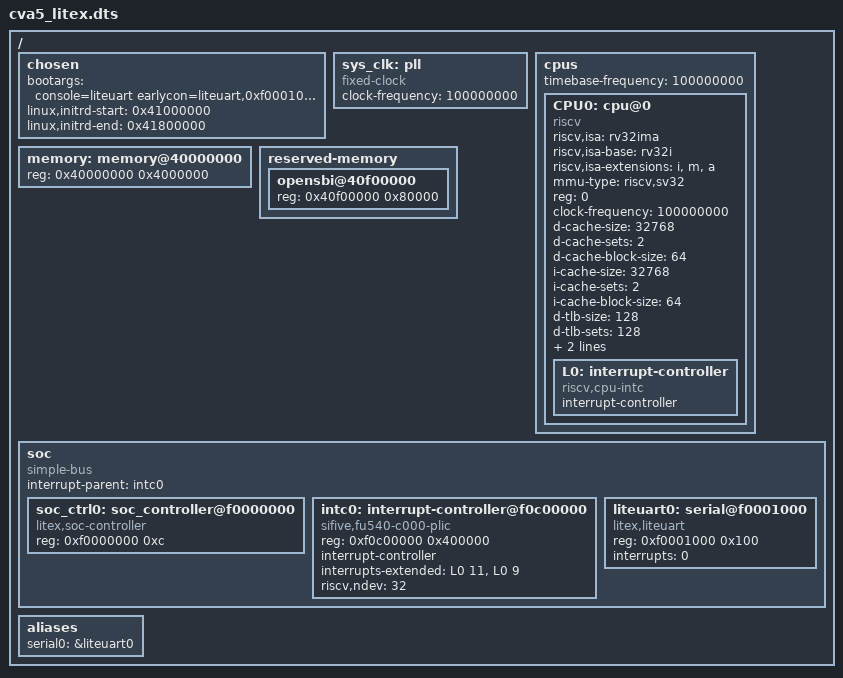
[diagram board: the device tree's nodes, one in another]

/dts-v1/;

/ {
        #address-cells = <1>;
        #size-cells    = <1>;


        chosen {
            bootargs = "console=liteuart earlycon=liteuart,0xf0001000 rootwait root=/dev/ram0";
            linux,initrd-start = <0x41000000>;
            linux,initrd-end   = <0x41800000>;
        };

        sys_clk: pll {
            compatible = "fixed-clock";
            #clock-cells = <0>;
            clock-frequency  = <100000000>;
        };

        cpus {
            #address-cells = <1>;
            #size-cells    = <0>;
            timebase-frequency = <100000000>;

            CPU0: cpu@0 {
                device_type = "cpu";
                compatible = "riscv";
                riscv,isa = "rv32ima";
                riscv,isa-base = "rv32i";
                riscv,isa-extensions = "i", "m", "a";
                mmu-type = "riscv,sv32";
                reg = <0>;
                clock-frequency = <100000000>;
                status = "okay";
                
                d-cache-size = <32768>;
                d-cache-sets = <2>;
                d-cache-block-size = <64>;

                i-cache-size = <32768>;
                i-cache-sets = <2>;
                i-cache-block-size = <64>;

                
                d-tlb-size = <128>;
                d-tlb-sets = <128>;

                i-tlb-size = <128>;
                i-tlb-sets = <128>;

                
                L0: interrupt-controller {
                    #address-cells = <0>;
                    #interrupt-cells = <0x00000001>;
                    interrupt-controller;
                    compatible = "riscv,cpu-intc";
                };
            };

            
        };

        memory: memory@40000000 {
            device_type = "memory";
            reg = <0x40000000 0x4000000>;
        };

        reserved-memory {
            #address-cells = <1>;
            #size-cells    = <1>;
            ranges;

            opensbi@40f00000 {
                reg = <0x40f00000 0x80000>;
            };

        };

        soc {
            #address-cells = <1>;
            #size-cells    = <1>;
            compatible = "simple-bus";
            interrupt-parent = <&intc0>;
            ranges;

            soc_ctrl0: soc_controller@f0000000 {
                compatible = "litex,soc-controller";
                reg = <0xf0000000 0xc>;
                status = "okay";
            };

            intc0: interrupt-controller@f0c00000 {
                compatible = "sifive,fu540-c000-plic", "sifive,plic-1.0.0";
                reg = <0xf0c00000 0x400000>;
                #address-cells = <0>;
                #interrupt-cells = <1>;
                interrupt-controller;
                interrupts-extended = <
                    &L0 11 &L0 9>;
                riscv,ndev = <32>;
                
            };

            liteuart0: serial@f0001000 {
                compatible = "litex,liteuart";
                reg = <0xf0001000 0x100>;
                interrupts = <0>;
                status = "okay";
            };

        };

        aliases {

                serial0 = &liteuart0;

        };

};
